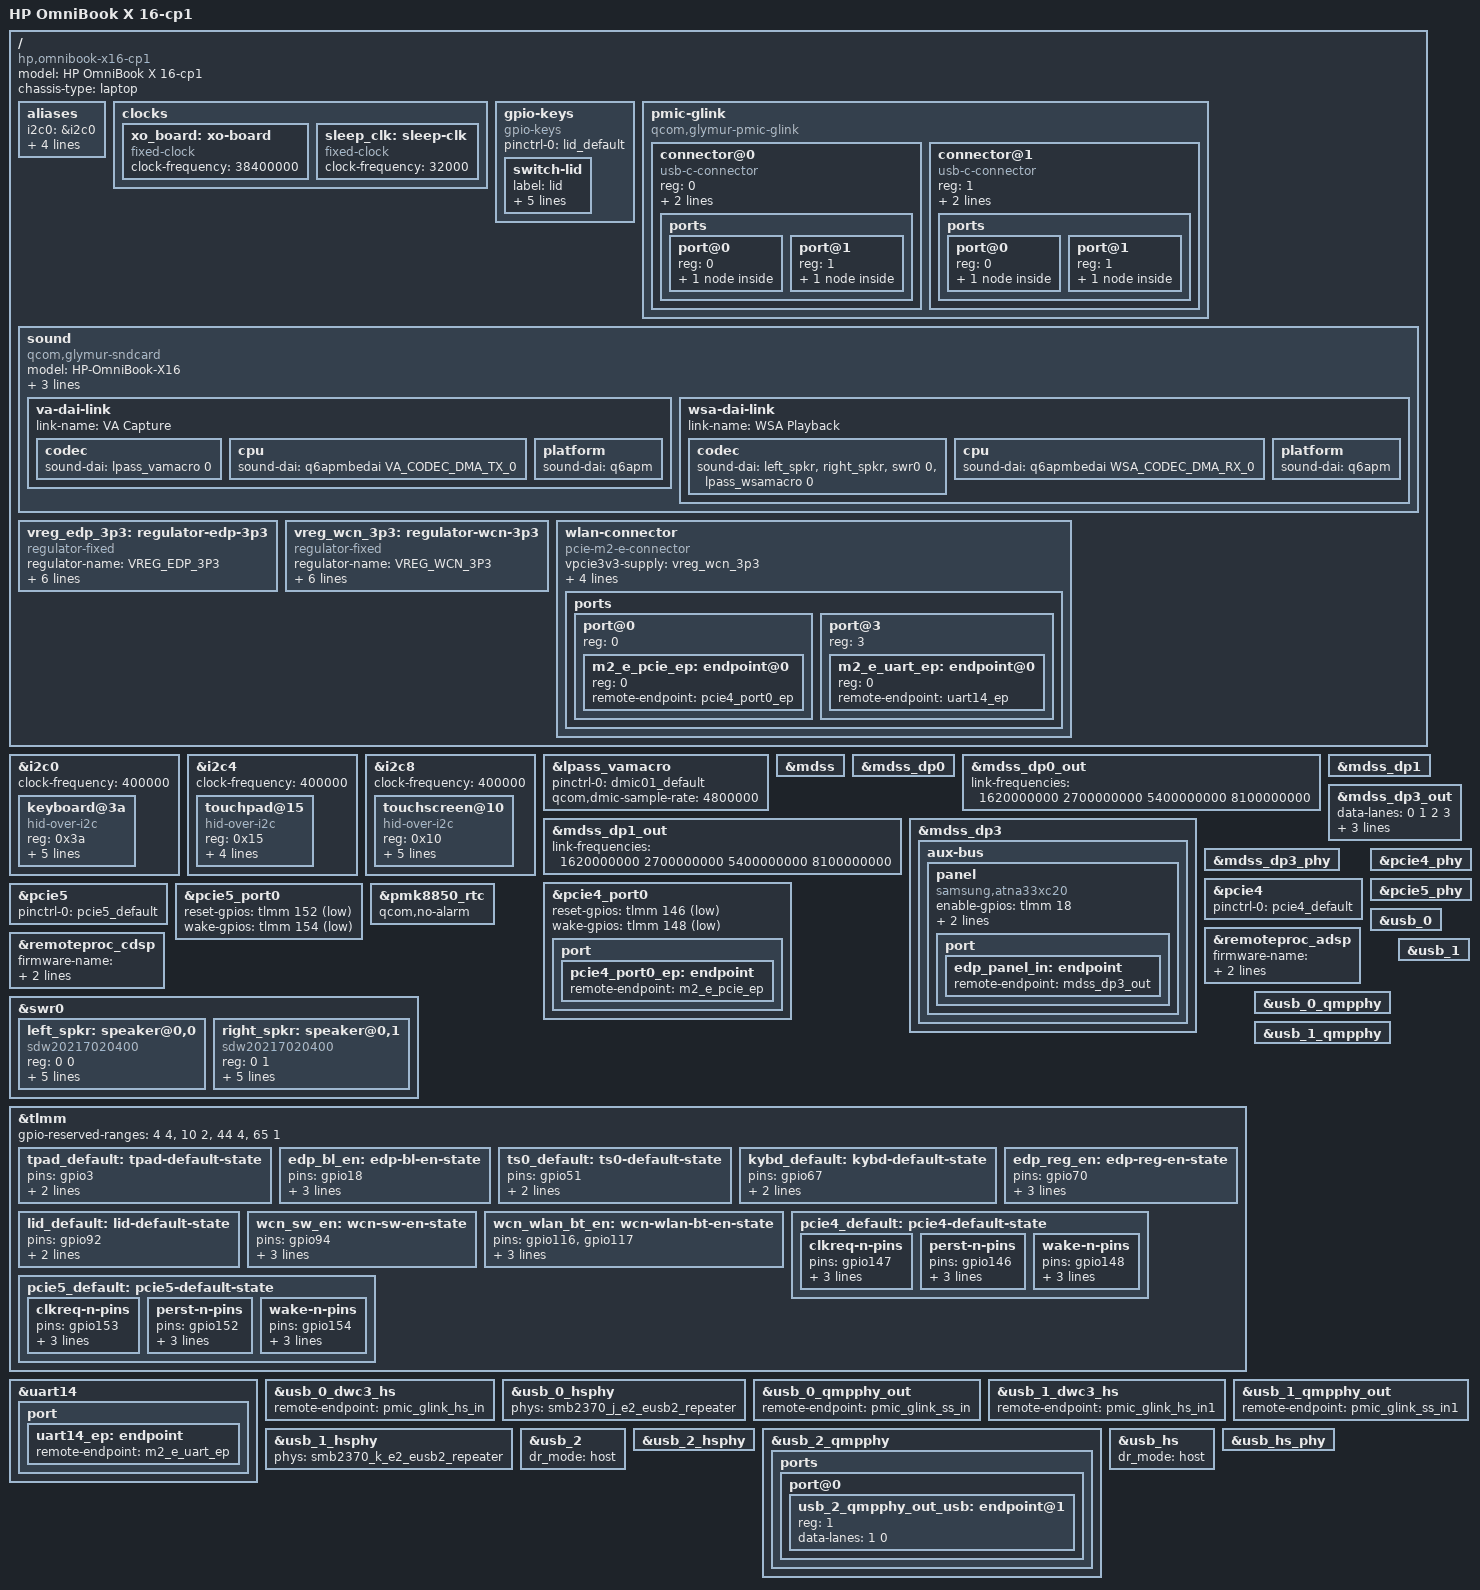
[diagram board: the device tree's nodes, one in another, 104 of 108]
// SPDX-License-Identifier: BSD-3-Clause
/*
 * Copyright (c) Qualcomm Technologies, Inc. and/or its subsidiaries.
 * Copyright (c) 2026 Jeff Roach <jeff.roach0@gmail.com>
 */
/dts-v1/;

#include "mahua.dtsi"

#include <dt-bindings/gpio/gpio.h>
#include <dt-bindings/input/gpio-keys.h>
#include <dt-bindings/input/input.h>
#include <dt-bindings/interrupt-controller/irq.h>
#include <dt-bindings/sound/qcom,q6dsp-lpass-ports.h>

/ {
	model = "HP OmniBook X 16-cp1";
	compatible = "hp,omnibook-x16-cp1", "qcom,mahua";
	chassis-type = "laptop";

	aliases {
		i2c0 = &i2c0;
		i2c4 = &i2c4;
		i2c8 = &i2c8;
		serial0 = &uart21;
		serial1 = &uart14;
	};

	clocks {
		xo_board: xo-board {
			compatible = "fixed-clock";
			clock-frequency = <38400000>;
			#clock-cells = <0>;
		};

		sleep_clk: sleep-clk {
			compatible = "fixed-clock";
			clock-frequency = <32000>;
			#clock-cells = <0>;
		};
	};

	gpio-keys {
		compatible = "gpio-keys";

		pinctrl-0 = <&lid_default>;
		pinctrl-names = "default";

		switch-lid {
			label = "lid";
			gpios = <&tlmm 92 GPIO_ACTIVE_LOW>;
			linux,input-type = <EV_SW>;
			linux,code = <SW_LID>;
			wakeup-source;
			wakeup-event-action = <EV_ACT_DEASSERTED>;
		};
	};

	pmic-glink {
		compatible = "qcom,glymur-pmic-glink",
			     "qcom,pmic-glink";
		#address-cells = <1>;
		#size-cells = <0>;

		/* Left rear USB-C port */
		connector@0 {
			compatible = "usb-c-connector";
			reg = <0>;
			power-role = "dual";
			data-role = "dual";

			ports {
				#address-cells = <1>;
				#size-cells = <0>;

				port@0 {
					reg = <0>;

					pmic_glink_hs_in: endpoint {
						remote-endpoint = <&usb_0_dwc3_hs>;
					};
				};

				port@1 {
					reg = <1>;

					pmic_glink_ss_in: endpoint {
						remote-endpoint = <&usb_0_qmpphy_out>;
					};
				};
			};
		};

		/* Left front USB-C port */
		connector@1 {
			compatible = "usb-c-connector";
			reg = <1>;
			power-role = "dual";
			data-role = "dual";

			ports {
				#address-cells = <1>;
				#size-cells = <0>;

				port@0 {
					reg = <0>;

					pmic_glink_hs_in1: endpoint {
						remote-endpoint = <&usb_1_dwc3_hs>;
					};
				};

				port@1 {
					reg = <1>;

					pmic_glink_ss_in1: endpoint {
						remote-endpoint = <&usb_1_qmpphy_out>;
					};
				};
			};
		};
	};

	sound {
		compatible = "qcom,glymur-sndcard";
		model = "HP-OmniBook-X16";

		audio-routing = "SpkrLeft IN", "WSA WSA_SPK1 OUT",
				"SpkrRight IN", "WSA WSA_SPK2 OUT",
				"VA DMIC0", "vdd-micb",
				"VA DMIC1", "vdd-micb";

		va-dai-link {
			link-name = "VA Capture";

			codec {
				sound-dai = <&lpass_vamacro 0>;
			};

			cpu {
				sound-dai = <&q6apmbedai VA_CODEC_DMA_TX_0>;
			};

			platform {
				sound-dai = <&q6apm>;
			};
		};

		wsa-dai-link {
			link-name = "WSA Playback";

			codec {
				sound-dai = <&left_spkr>, <&right_spkr>,
					    <&swr0 0>, <&lpass_wsamacro 0>;
			};

			cpu {
				sound-dai = <&q6apmbedai WSA_CODEC_DMA_RX_0>;
			};

			platform {
				sound-dai = <&q6apm>;
			};
		};
	};

	vreg_edp_3p3: regulator-edp-3p3 {
		compatible = "regulator-fixed";

		regulator-name = "VREG_EDP_3P3";
		regulator-min-microvolt = <3300000>;
		regulator-max-microvolt = <3300000>;

		gpio = <&tlmm 70 GPIO_ACTIVE_HIGH>;
		enable-active-high;

		pinctrl-0 = <&edp_reg_en>;
		pinctrl-names = "default";

		regulator-boot-on;
	};

	vreg_wcn_3p3: regulator-wcn-3p3 {
		compatible = "regulator-fixed";

		regulator-name = "VREG_WCN_3P3";
		regulator-min-microvolt = <3300000>;
		regulator-max-microvolt = <3300000>;

		gpio = <&tlmm 94 GPIO_ACTIVE_HIGH>;
		enable-active-high;

		pinctrl-0 = <&wcn_sw_en>;
		pinctrl-names = "default";

		regulator-boot-on;
	};

	/* Qualcomm QCC2072 Wi-Fi/Bluetooth module in an M.2 key E slot */
	wlan-connector {
		compatible = "pcie-m2-e-connector";
		vpcie3v3-supply = <&vreg_wcn_3p3>;
		vpcie1v8-supply = <&vreg_l15b0>;

		w-disable1-gpios = <&tlmm 117 GPIO_ACTIVE_LOW>;
		w-disable2-gpios = <&tlmm 116 GPIO_ACTIVE_LOW>;

		pinctrl-0 = <&wcn_wlan_bt_en>;
		pinctrl-names = "default";

		ports {
			#address-cells = <1>;
			#size-cells = <0>;

			port@0 {
				reg = <0>;
				#address-cells = <1>;
				#size-cells = <0>;

				m2_e_pcie_ep: endpoint@0 {
					reg = <0>;
					remote-endpoint = <&pcie4_port0_ep>;
				};
			};

			port@3 {
				reg = <3>;
				#address-cells = <1>;
				#size-cells = <0>;

				m2_e_uart_ep: endpoint@0 {
					reg = <0>;
					remote-endpoint = <&uart14_ep>;
				};
			};
		};
	};
};

&i2c0 {
	clock-frequency = <400000>;

	status = "okay";

	keyboard@3a {
		compatible = "hid-over-i2c";
		reg = <0x3a>;

		hid-descr-addr = <0x1>;
		interrupts-extended = <&tlmm 67 IRQ_TYPE_LEVEL_LOW>;

		pinctrl-0 = <&kybd_default>;
		pinctrl-names = "default";

		wakeup-source;
	};
};

&i2c4 {
	clock-frequency = <400000>;

	status = "okay";

	touchpad@15 {
		compatible = "hid-over-i2c";
		reg = <0x15>;

		hid-descr-addr = <0x1>;
		interrupts-extended = <&tlmm 3 IRQ_TYPE_LEVEL_LOW>;

		pinctrl-0 = <&tpad_default>;
		pinctrl-names = "default";

		wakeup-source;
	};
};

&i2c8 {
	clock-frequency = <400000>;

	status = "okay";

	touchscreen@10 {
		compatible = "hid-over-i2c";
		reg = <0x10>;

		hid-descr-addr = <0x1>;
		interrupts-extended = <&tlmm 51 IRQ_TYPE_LEVEL_LOW>;

		post-power-on-delay-ms = <200>;

		pinctrl-0 = <&ts0_default>;
		pinctrl-names = "default";
	};
};

&lpass_vamacro {
	pinctrl-0 = <&dmic01_default>;
	pinctrl-names = "default";

	qcom,dmic-sample-rate = <4800000>;
};

&mdss {
	status = "okay";
};

&mdss_dp0 {
	status = "okay";
};

&mdss_dp0_out {
	link-frequencies = /bits/ 64 <1620000000 2700000000 5400000000 8100000000>;
};

&mdss_dp1 {
	status = "okay";
};

&mdss_dp1_out {
	link-frequencies = /bits/ 64 <1620000000 2700000000 5400000000 8100000000>;
};

&mdss_dp3 {
	/delete-property/ #sound-dai-cells;

	status = "okay";

	aux-bus {
		panel {
			compatible = "samsung,atna33xc20";
			enable-gpios = <&tlmm 18 GPIO_ACTIVE_HIGH>;
			power-supply = <&vreg_edp_3p3>;

			pinctrl-0 = <&edp_bl_en>;
			pinctrl-names = "default";

			port {
				edp_panel_in: endpoint {
					remote-endpoint = <&mdss_dp3_out>;
				};
			};
		};
	};
};

&mdss_dp3_out {
	data-lanes = <0 1 2 3>;
	link-frequencies = /bits/ 64 <1620000000 2700000000 5400000000 8100000000>;

	remote-endpoint = <&edp_panel_in>;
};

&mdss_dp3_phy {
	status = "okay";
};

&pcie4 {
	pinctrl-0 = <&pcie4_default>;
	pinctrl-names = "default";

	status = "okay";
};

&pcie4_phy {
	status = "okay";
};

&pcie4_port0 {
	reset-gpios = <&tlmm 146 GPIO_ACTIVE_LOW>;
	wake-gpios = <&tlmm 148 GPIO_ACTIVE_LOW>;

	port {
		pcie4_port0_ep: endpoint {
			remote-endpoint = <&m2_e_pcie_ep>;
		};
	};
};

&pcie5 {
	pinctrl-0 = <&pcie5_default>;
	pinctrl-names = "default";

	status = "okay";
};

&pcie5_phy {
	status = "okay";
};

&pcie5_port0 {
	reset-gpios = <&tlmm 152 GPIO_ACTIVE_LOW>;
	wake-gpios = <&tlmm 154 GPIO_ACTIVE_LOW>;

	status = "okay";
};

&pmk8850_rtc {
	qcom,no-alarm;
};

&remoteproc_adsp {
	firmware-name = "qcom/glymur/hp/omnibook-x16/qcadsp8480.mbn",
			"qcom/glymur/hp/omnibook-x16/adsp_dtbs.elf";

	status = "okay";
};

&remoteproc_cdsp {
	firmware-name = "qcom/glymur/hp/omnibook-x16/qccdsp8480.mbn",
			"qcom/glymur/hp/omnibook-x16/cdsp_dtbs.elf";

	status = "okay";
};

&swr0 {
	status = "okay";

	/* WSA8845, left speaker */
	left_spkr: speaker@0,0 {
		compatible = "sdw20217020400";
		reg = <0 0>;
		reset-gpios = <&lpass_tlmm 12 GPIO_ACTIVE_LOW>;
		#sound-dai-cells = <0>;
		sound-name-prefix = "SpkrLeft";
		vdd-1p8-supply = <&vreg_l15b0>;
		vdd-io-supply = <&vreg_l18b0>;
		qcom,port-mapping = <1 2 3 7 12 14>;
	};

	/* WSA8845, right speaker */
	right_spkr: speaker@0,1 {
		compatible = "sdw20217020400";
		reg = <0 1>;
		reset-gpios = <&lpass_tlmm 12 GPIO_ACTIVE_LOW>;
		#sound-dai-cells = <0>;
		sound-name-prefix = "SpkrRight";
		vdd-1p8-supply = <&vreg_l15b0>;
		vdd-io-supply = <&vreg_l18b0>;
		qcom,port-mapping = <4 5 6 7 13 15>;
	};
};

&tlmm {
	gpio-reserved-ranges = <4 4>, /* EC TZ Secure I3C */
			       <10 2>, /* OOB UART */
			       <44 4>, /* Security SPI (TPM) */
			       <65 1>; /* EC reset */

	tpad_default: tpad-default-state {
		pins = "gpio3";
		function = "gpio";
		bias-disable;
	};

	edp_bl_en: edp-bl-en-state {
		pins = "gpio18";
		function = "gpio";
		drive-strength = <16>;
		bias-disable;
	};

	ts0_default: ts0-default-state {
		pins = "gpio51";
		function = "gpio";
		bias-disable;
	};

	kybd_default: kybd-default-state {
		pins = "gpio67";
		function = "gpio";
		bias-disable;
	};

	edp_reg_en: edp-reg-en-state {
		pins = "gpio70";
		function = "gpio";
		drive-strength = <16>;
		bias-disable;
	};

	lid_default: lid-default-state {
		pins = "gpio92";
		function = "gpio";
		bias-disable;
	};

	wcn_sw_en: wcn-sw-en-state {
		pins = "gpio94";
		function = "gpio";
		drive-strength = <2>;
		bias-disable;
	};

	wcn_wlan_bt_en: wcn-wlan-bt-en-state {
		pins = "gpio116", "gpio117";
		function = "gpio";
		drive-strength = <2>;
		bias-disable;
	};

	pcie4_default: pcie4-default-state {
		clkreq-n-pins {
			pins = "gpio147";
			function = "pcie4_clk_req_n";
			drive-strength = <2>;
			bias-pull-up;
		};

		perst-n-pins {
			pins = "gpio146";
			function = "gpio";
			drive-strength = <2>;
			bias-disable;
		};

		wake-n-pins {
			pins = "gpio148";
			function = "gpio";
			drive-strength = <2>;
			bias-pull-up;
		};
	};

	pcie5_default: pcie5-default-state {
		clkreq-n-pins {
			pins = "gpio153";
			function = "pcie5_clk_req_n";
			drive-strength = <2>;
			bias-pull-up;
		};

		perst-n-pins {
			pins = "gpio152";
			function = "gpio";
			drive-strength = <2>;
			bias-disable;
		};

		wake-n-pins {
			pins = "gpio154";
			function = "gpio";
			drive-strength = <2>;
			bias-pull-up;
		};
	};
};

&uart14 {
	status = "okay";

	port {
		uart14_ep: endpoint {
			remote-endpoint = <&m2_e_uart_ep>;
		};
	};
};

&usb_0 {
	status = "okay";
};

&usb_0_dwc3_hs {
	remote-endpoint = <&pmic_glink_hs_in>;
};

&usb_0_hsphy {
	phys = <&smb2370_j_e2_eusb2_repeater>;

	status = "okay";
};

&usb_0_qmpphy {
	status = "okay";
};

&usb_0_qmpphy_out {
	remote-endpoint = <&pmic_glink_ss_in>;
};

&usb_1 {
	status = "okay";
};

&usb_1_dwc3_hs {
	remote-endpoint = <&pmic_glink_hs_in1>;
};

&usb_1_hsphy {
	phys = <&smb2370_k_e2_eusb2_repeater>;

	status = "okay";
};

&usb_1_qmpphy {
	status = "okay";
};

&usb_1_qmpphy_out {
	remote-endpoint = <&pmic_glink_ss_in1>;
};

/* USB-A port on the right side */
&usb_2 {
	dr_mode = "host";

	/delete-property/ usb-role-switch;

	status = "okay";
};

&usb_2_hsphy {
	status = "okay";
};

&usb_2_qmpphy {
	/delete-property/ mode-switch;
	/delete-property/ orientation-switch;

	status = "okay";

	ports {
		port@0 {
			#address-cells = <1>;
			#size-cells = <0>;

			/delete-node/ endpoint;

			usb_2_qmpphy_out_usb: endpoint@1 {
				reg = <1>;

				data-lanes = <1 0>;
			};
		};
	};
};

/* Internal USB 2.0 host for the webcam */
&usb_hs {
	dr_mode = "host";

	status = "okay";
};

&usb_hs_phy {
	status = "okay";
};
